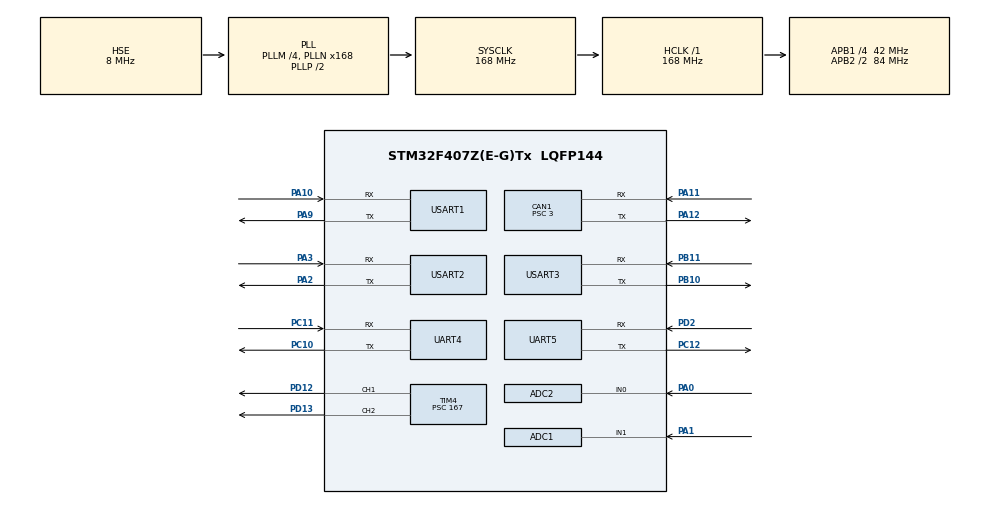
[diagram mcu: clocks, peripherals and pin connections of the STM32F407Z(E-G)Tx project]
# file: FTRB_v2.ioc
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ADC1.Channel-0\#ChannelRegularConversion=ADC_CHANNEL_1
ADC1.NbrOfConversionFlag=1
ADC1.Rank-0\#ChannelRegularConversion=1
ADC1.SamplingTime-0\#ChannelRegularConversion=ADC_SAMPLETIME_3CYCLES
ADC1.master=1
ADC2.Channel-1\#ChannelRegularConversion=ADC_CHANNEL_0
ADC2.NbrOfConversionFlag=1
ADC2.Rank-1\#ChannelRegularConversion=1
ADC2.SamplingTime-1\#ChannelRegularConversion=ADC_SAMPLETIME_3CYCLES
CAN1.BS1=CAN_BS1_9TQ
CAN1.BS2=CAN_BS2_4TQ
CAN1.CalculateBaudRate=1000000
CAN1.CalculateTimeBit=1000
CAN1.CalculateTimeQuantum=71.42857142857143
CAN1.NART=ENABLE
CAN1.Prescaler=3
FREERTOS.Tasks01=defaultTask,24,128,StartDefaultTask,Default,NULL,Dynamic,NULL,NULL;SensorTask,40,128,StartSensorTask,Default,NULL,Dynamic,NULL,NULL;MotorTask,8,128,StartMotorTask,Default,NULL,Dynamic,NULL,NULL
Mcu.Family=STM32F4
Mcu.Name=STM32F407Z(E-G)Tx
Mcu.Package=LQFP144
NVIC.ADC_IRQn=true\:5\:0\:false\:false\:true\:true\:true\:true\:true
NVIC.CAN1_RX0_IRQn=true\:5\:0\:false\:false\:true\:true\:true\:true\:true
NVIC.CAN1_RX1_IRQn=true\:5\:0\:false\:false\:true\:true\:true\:true\:true
NVIC.PriorityGroup=NVIC_PRIORITYGROUP_4
NVIC.TIM8_UP_TIM13_IRQn=true\:15\:0\:false\:false\:true\:false\:false\:true\:true
NVIC.TimeBase=TIM8_UP_TIM13_IRQn
NVIC.TimeBaseIP=TIM8
NVIC.UART4_IRQn=true\:5\:0\:false\:false\:true\:true\:true\:true\:true
NVIC.UART5_IRQn=true\:5\:0\:false\:false\:true\:true\:true\:true\:true
NVIC.USART1_IRQn=true\:5\:0\:false\:false\:true\:true\:true\:true\:true
NVIC.USART2_IRQn=true\:5\:0\:false\:false\:true\:true\:true\:true\:true
NVIC.USART3_IRQn=true\:5\:0\:false\:false\:true\:true\:true\:true\:true
PA0-WKUP.Signal=ADCx_IN0
PA1.Signal=ADCx_IN1
PA10.Mode=Asynchronous
PA10.Signal=USART1_RX
PA11.Mode=CAN_Activate
PA11.Signal=CAN1_RX
PA12.Mode=CAN_Activate
PA12.Signal=CAN1_TX
PA13.Mode=Serial_Wire
PA13.Signal=SYS_JTMS-SWDIO
PA14.Mode=Serial_Wire
PA14.Signal=SYS_JTCK-SWCLK
PA2.Mode=Asynchronous
PA2.Signal=USART2_TX
PA3.Mode=Asynchronous
PA3.Signal=USART2_RX
PA9.Mode=Asynchronous
PA9.Signal=USART1_TX
PB10.Mode=Asynchronous
PB10.Signal=USART3_TX
PB11.Mode=Asynchronous
PB11.Signal=USART3_RX
PC10.Mode=Asynchronous
PC10.Signal=UART4_TX
PC11.Mode=Asynchronous
PC11.Signal=UART4_RX
PC12.Mode=Asynchronous
PC12.Signal=UART5_TX
PD12.Signal=S_TIM4_CH1
PD13.Signal=S_TIM4_CH2
PD2.Mode=Asynchronous
PD2.Signal=UART5_RX
PH0-OSC_IN.Mode=HSE-External-Oscillator
PH0-OSC_IN.Signal=RCC_OSC_IN
PH1-OSC_OUT.Mode=HSE-External-Oscillator
PH1-OSC_OUT.Signal=RCC_OSC_OUT
ProjectManager.HeapSize=0x200
ProjectManager.StackSize=0x400
ProjectManager.TargetToolchain=Makefile
RCC.48MHZClocksFreq_Value=84000000
RCC.AHBFreq_Value=168000000
RCC.APB1CLKDivider=RCC_HCLK_DIV4
RCC.APB1Freq_Value=42000000
RCC.APB1TimFreq_Value=84000000
RCC.APB2CLKDivider=RCC_HCLK_DIV2
RCC.APB2Freq_Value=84000000
RCC.APB2TimFreq_Value=168000000
RCC.CortexFreq_Value=168000000
RCC.HCLKFreq_Value=168000000
RCC.HSE_VALUE=8000000
RCC.HSI_VALUE=16000000
RCC.LSE_VALUE=32768
RCC.PLLM=4
RCC.PLLN=168
RCC.PLLSourceVirtual=RCC_PLLSOURCE_HSE
RCC.SYSCLKFreq_VALUE=168000000
RCC.SYSCLKSource=RCC_SYSCLKSOURCE_PLLCLK
RCC.VCOOutputFreq_Value=336000000
SH.ADCx_IN0.0=ADC2_IN0,IN0
SH.ADCx_IN1.0=ADC1_IN1,IN1
SH.S_TIM4_CH1.0=TIM4_CH1,PWM Generation1 CH1
SH.S_TIM4_CH2.0=TIM4_CH2,PWM Generation2 CH2
TIM4.Channel-PWM\ Generation1\ CH1=TIM_CHANNEL_1
TIM4.Channel-PWM\ Generation2\ CH2=TIM_CHANNEL_2
TIM4.Period=2000
TIM4.Prescaler=167
UART4.VirtualMode=Asynchronous
UART5.VirtualMode=Asynchronous
USART1.VirtualMode=VM_ASYNC
USART2.VirtualMode=VM_ASYNC
USART3.VirtualMode=VM_ASYNC
VP_FREERTOS_VS_CMSIS_V2.Mode=CMSIS_V2
VP_SYS_VS_tim8.Mode=TIM8
board=custom

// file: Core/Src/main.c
/* USER CODE BEGIN Header */
/**
  ******************************************************************************
  * @file           : main.c
  * @brief          : Main program body
  ******************************************************************************
  * @attention
  *
  * Copyright (c) 2023 STMicroelectronics.
  * All rights reserved.
  *
  * This software is licensed under terms that can be found in the LICENSE file
  * in the root directory of this software component.
  * If no LICENSE file comes with this software, it is provided AS-IS.
  *
  ******************************************************************************
  */
/* USER CODE END Header */
#include "main.h"
#include "cmsis_os.h"
#include "adc.h"
#include "can.h"
#include "tim.h"
#include "usart.h"
#include "gpio.h"

/* USER CODE BEGIN Includes */
#include "bsp_can.h"
/* USER CODE END Includes */

void SystemClock_Config(void);
void MX_FREERTOS_Init(void);

int main(void)
{

  /* MCU Configuration--------------------------------------------------------*/

  /* Reset of all peripherals, Initializes the Flash interface and the Systick. */
  HAL_Init();

  /* Configure the system clock */
  SystemClock_Config();

  /* Initialize all configured peripherals */
  MX_GPIO_Init();
  MX_CAN1_Init();
  MX_UART4_Init();
  MX_UART5_Init();
  MX_USART1_UART_Init();
  MX_USART2_UART_Init();
  MX_USART3_UART_Init();
  MX_ADC1_Init();
  MX_TIM4_Init();
  MX_ADC2_Init();
  /* USER CODE BEGIN 2 */
  BSP_CAN_Init();
  /* USER CODE END 2 */

  /* Init scheduler */
  osKernelInitialize();  /* Call init function for freertos objects (in freertos.c) */
  MX_FREERTOS_Init();

  /* Start scheduler */
  osKernelStart();

  /* We should never get here as control is now taken by the scheduler */
  /* Infinite loop */
  while (1)
  {

  }
}

void SystemClock_Config(void)
{
  RCC_OscInitTypeDef RCC_OscInitStruct = {0};
  RCC_ClkInitTypeDef RCC_ClkInitStruct = {0};

  /** Configure the main internal regulator output voltage
  */
  __HAL_RCC_PWR_CLK_ENABLE();
  __HAL_PWR_VOLTAGESCALING_CONFIG(PWR_REGULATOR_VOLTAGE_SCALE1);

  /** Initializes the RCC Oscillators according to the specified parameters
  * in the RCC_OscInitTypeDef structure.
  */
  RCC_OscInitStruct.OscillatorType = RCC_OSCILLATORTYPE_HSE;
  RCC_OscInitStruct.HSEState = RCC_HSE_ON;
  RCC_OscInitStruct.PLL.PLLState = RCC_PLL_ON;
  RCC_OscInitStruct.PLL.PLLSource = RCC_PLLSOURCE_HSE;
  RCC_OscInitStruct.PLL.PLLM = 4;
  RCC_OscInitStruct.PLL.PLLN = 168;
  RCC_OscInitStruct.PLL.PLLP = RCC_PLLP_DIV2;
  RCC_OscInitStruct.PLL.PLLQ = 4;
  if (HAL_RCC_OscConfig(&RCC_OscInitStruct) != HAL_OK)
  {
    Error_Handler();
  }

  /** Initializes the CPU, AHB and APB buses clocks
  */
  RCC_ClkInitStruct.ClockType = RCC_CLOCKTYPE_HCLK|RCC_CLOCKTYPE_SYSCLK
                              |RCC_CLOCKTYPE_PCLK1|RCC_CLOCKTYPE_PCLK2;
  RCC_ClkInitStruct.SYSCLKSource = RCC_SYSCLKSOURCE_PLLCLK;
  RCC_ClkInitStruct.AHBCLKDivider = RCC_SYSCLK_DIV1;
  RCC_ClkInitStruct.APB1CLKDivider = RCC_HCLK_DIV4;
  RCC_ClkInitStruct.APB2CLKDivider = RCC_HCLK_DIV2;

  if (HAL_RCC_ClockConfig(&RCC_ClkInitStruct, FLASH_LATENCY_5) != HAL_OK)
  {
    Error_Handler();
  }
}

void HAL_TIM_PeriodElapsedCallback(TIM_HandleTypeDef *htim)
{
  if (htim->Instance == TIM8) {
    HAL_IncTick();
  }
}

void Error_Handler(void)
{
  __disable_irq();
  while (1)
  {
  }
}

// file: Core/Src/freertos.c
/* USER CODE BEGIN Header */
/**
  ******************************************************************************
  * File Name          : freertos.c
  * Description        : Code for freertos applications
  ******************************************************************************
  * @attention
  *
  * Copyright (c) 2023 STMicroelectronics.
  * All rights reserved.
  *
  * This software is licensed under terms that can be found in the LICENSE file
  * in the root directory of this software component.
  * If no LICENSE file comes with this software, it is provided AS-IS.
  *
  ******************************************************************************
  */
/* USER CODE END Header */

#include "FreeRTOS.h"
#include "task.h"
#include "main.h"
#include "cmsis_os.h"

/* USER CODE BEGIN Includes */
#include "app.h"
/* USER CODE END Includes */

/* USER CODE BEGIN Variables */
uint8_t robot_created = 0;
/* USER CODE END Variables */
/* Definitions for defaultTask */
osThreadId_t defaultTaskHandle;
const osThreadAttr_t defaultTask_attributes = {
  .name = "defaultTask",
  .stack_size = 128 * 4,
  .priority = (osPriority_t) osPriorityNormal,
};
/* Definitions for SensorTask */
osThreadId_t SensorTaskHandle;
const osThreadAttr_t SensorTask_attributes = {
  .name = "SensorTask",
  .stack_size = 128 * 4,
  .priority = (osPriority_t) osPriorityHigh,
};
/* Definitions for MotorTask */
osThreadId_t MotorTaskHandle;
const osThreadAttr_t MotorTask_attributes = {
  .name = "MotorTask",
  .stack_size = 128 * 4,
  .priority = (osPriority_t) osPriorityLow,
};

void StartDefaultTask(void *argument);
void StartSensorTask(void *argument);
void StartMotorTask(void *argument);

void MX_FREERTOS_Init(void); /* (MISRA C 2004 rule 8.1) */

void MX_FREERTOS_Init(void) {
/* USER CODE BEGIN Header */
/**
  ******************************************************************************
  * File Name          : freertos.c
  * Description        : Code for freertos applications
  ******************************************************************************
  * @attention
  *
  * Copyright (c) 2023 STMicroelectronics.
  * All rights reserved.
  *
  * This software is licensed under terms that can be found in the LICENSE file
  * in the root directory of this software component.
  * If no LICENSE file comes with this software, it is provided AS-IS.
  *
  ******************************************************************************
  */
/* USER CODE END Header */
  defaultTaskHandle = osThreadNew(StartDefaultTask, NULL, &defaultTask_attributes);
  SensorTaskHandle = osThreadNew(StartSensorTask, NULL, &SensorTask_attributes);
  MotorTaskHandle = osThreadNew(StartMotorTask, NULL, &MotorTask_attributes);

}

void StartDefaultTask(void *argument)
{
  /* USER CODE BEGIN StartDefaultTask */
  robot = Robot_Create();
  robot_created = 1;
  /* Infinite loop */
  for(;;)
  {
    osDelay(1);
  }
  /* USER CODE END StartDefaultTask */
}

void StartSensorTask(void *argument)
{
  /* USER CODE BEGIN StartSensorTask */
  /* Infinite loop */
  for(;;)
  {
    if(robot_created){
      WT53D_Send_All();
    }
    osDelay(10);
  }
  /* USER CODE END StartSensorTask */
}

void StartMotorTask(void *argument)
{
  /* USER CODE BEGIN StartMotorTask */
  /* Infinite loop */
  for(;;)
  {
    if(robot_created){
      Motor_Send_Empty();
    }
    osDelay(10);
  }
  /* USER CODE END StartMotorTask */
}
